AUTOSAR XML (schema 4-2-2)
package /Company/Components
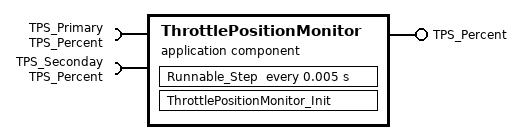
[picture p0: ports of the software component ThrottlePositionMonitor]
  application sw component type ThrottlePositionMonitor
    require port TPS_Primary: nonqueued-receiver-com-spec{data-element=Value, init-value=ComSpec0db1e2d4_49b77d189fc42c54:0}, required-interface=TPS_Percent
    require port TPS_Seconday: nonqueued-receiver-com-spec{data-element=Value, init-value=ComSpec2c92f608_f1354ff019949f7a:0}, required-interface=TPS_Percent
    provide port TPS_Percent: nonqueued-sender-com-spec{data-element=Value, init-value=ComSpec47d79e29_4d78b0445373e10b:0}, provided-interface=TPS_Percent
    behavior ThrottlePositionMonitor_InternalBehavior: handle-termination-and-restart=NO-SUPPORT
      timing event Event_Runnable_Step: start-on-event=Runnable_Step, period=0.005
      init event ThrottlePositionMonitor_InitEvent: start-on-event=ThrottlePositionMonitor_Init
      runnable Runnable_Step
        data-read-access:
          access IN_TPS_Primary_Value: accessed-variable=TPS_Primary.Value
          access IN_TPS_Seconday_Value: accessed-variable=TPS_Seconday.Value
        data-write-access:
          access OUT_TPS_Percent_Value: accessed-variable=TPS_Percent.Value
      runnable ThrottlePositionMonitor_Init
